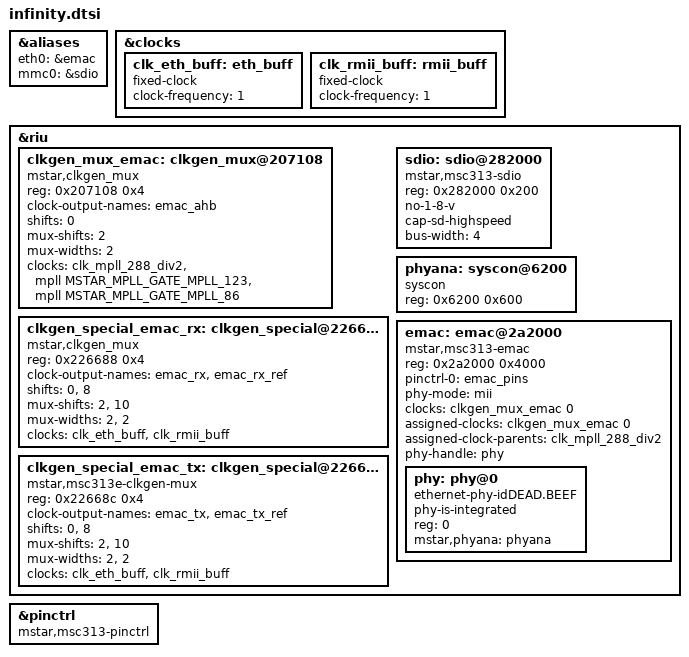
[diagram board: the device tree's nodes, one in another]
// SPDX-License-Identifier: GPL-2.0
/*
 * Copyright (c) 2019 thingy.jp.
 * Author: Daniel Palmer <daniel@0x0f.com>
 */

#include "mstar-v7.dtsi"

&aliases {
	eth0 = &emac;
	mmc0 = &sdio;
};

&clocks {
	clk_eth_buff: eth_buff {
		#clock-cells = <0>;
		compatible = "fixed-clock";
		clock-frequency = <1>;
	};
	clk_rmii_buff: rmii_buff {
		#clock-cells = <0>;
		compatible = "fixed-clock";
		clock-frequency = <1>;
	};
};

&riu {
	clkgen_mux_emac: clkgen_mux@207108 {
		compatible = "mstar,clkgen_mux";
		reg = <0x207108 0x4>;
		#clock-cells = <1>;
		clock-output-names = "emac_ahb";
		shifts = <0>;
		mux-shifts = <2>;
		mux-widths = <2>;
		clocks = <&clk_mpll_288_div2>,
			 <&mpll MSTAR_MPLL_GATE_MPLL_123>,
			 <&mpll MSTAR_MPLL_GATE_MPLL_86>;
			 /* from lan_atop ? */
	};

	clkgen_special_emac_rx: clkgen_special@226688 {
		compatible = "mstar,clkgen_mux";
		reg = <0x226688 0x4>;
		#clock-cells = <1>;
		clock-output-names = "emac_rx", "emac_rx_ref";
		shifts = <0>, <8>;
		mux-shifts = <2>, <10>;
		mux-widths = <2>, <2>;
		clocks = <&clk_eth_buff>,
			 <&clk_rmii_buff>;
	};

	clkgen_special_emac_tx: clkgen_special@22668c {
		compatible = "mstar,msc313e-clkgen-mux";
		reg = <0x22668c 0x4>;
		#clock-cells = <1>;
		clock-output-names = "emac_tx", "emac_tx_ref";
		shifts = <0>, <8>;
		mux-shifts = <2>, <10>;
		mux-widths = <2>, <2>;
		clocks = <&clk_eth_buff>,
			 <&clk_rmii_buff>;
	};

	sdio: sdio@282000 {
		compatible = "mstar,msc313-sdio";
		u-boot,dm-spl;
		u-boot,dm-preloc;
		reg = <0x282000 0x200>;
		no-1-8-v;
		cap-sd-highspeed;
		bus-width = <4>;
	};

	phyana: syscon@6200 {
		compatible = "syscon";
		reg = <0x6200 0x600>;
	};

	emac: emac@2a2000 {
		compatible = "mstar,msc313-emac";
		reg = <0x2a2000 0x4000>;
		pinctrl-names = "default";
		pinctrl-0 = <&emac_pins>;
		phy-mode = "mii";
		clocks = <&clkgen_mux_emac 0>;
		assigned-clocks = <&clkgen_mux_emac 0>;
		assigned-clock-parents = <&clk_mpll_288_div2>;
		phy-handle = <&phy>;
		phy: phy@0 {
			compatible = "ethernet-phy-idDEAD.BEEF";
			phy-is-integrated;
			reg = <0>;
			mstar,phyana = <&phyana>;
		};
	};
};

&pinctrl {
	compatible = "mstar,msc313-pinctrl";
};
